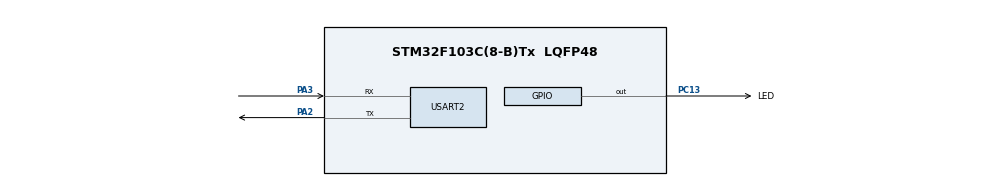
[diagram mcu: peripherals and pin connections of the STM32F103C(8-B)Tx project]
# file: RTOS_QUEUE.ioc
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Mcu.Family=STM32F1
PC15-OSC32_OUT.Mode=LSE-External-Oscillator
FREERTOS.Tasks01=xTaskHandler1,24,128,vTask1_DisplayMenu,Default,NULL,Dynamic,NULL,NULL
PD1-OSC_OUT.Mode=HSE-External-Oscillator
PC13-TAMPER-RTC.Signal=GPIO_Output
PD0-OSC_IN.Signal=RCC_OSC_IN
PC14-OSC32_IN.Signal=RCC_OSC32_IN
ProjectManager.StackSize=0x400
VP_FREERTOS_VS_CMSIS_V2.Mode=CMSIS_V2
PD1-OSC_OUT.Signal=RCC_OSC_OUT
FREERTOS.configUSE_IDLE_HOOK=1
PA13.Signal=SYS_JTMS-SWDIO
PA3.Mode=Asynchronous
VP_SYS_VS_tim3.Mode=TIM3
ProjectManager.TargetToolchain=STM32CubeIDE
FREERTOS.configUSE_MALLOC_FAILED_HOOK=1
PC15-OSC32_OUT.Signal=RCC_OSC32_OUT
PD0-OSC_IN.Mode=HSE-External-Oscillator
board=custom
PC13-TAMPER-RTC.GPIO_Label=LED
NVIC.TIM3_IRQn=true\:0\:0\:false\:false\:true\:false\:false\:true
RCC.APB2Freq_Value=8000000
PC14-OSC32_IN.Mode=LSE-External-Oscillator
PC13-TAMPER-RTC.PinState=GPIO_PIN_RESET
PA14.Mode=Serial_Wire
PA13.Mode=Serial_Wire
Mcu.Name=STM32F103C(8-B)Tx
PA2.Signal=USART2_TX
Mcu.Package=LQFP48
NVIC.TimeBase=TIM3_IRQn
USART2.VirtualMode=VM_ASYNC
NVIC.TimeBaseIP=TIM3
PA14.Signal=SYS_JTCK-SWCLK
ProjectManager.HeapSize=0x200
NVIC.PriorityGroup=NVIC_PRIORITYGROUP_4
PA2.Mode=Asynchronous
RCC.APB1Freq_Value=8000000
PA3.Signal=USART2_RX

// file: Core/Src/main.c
/* USER CODE BEGIN Header */
/**
  ******************************************************************************
  * @file           : main.c
  * @brief          : Main program body
  ******************************************************************************
  * @attention
  *
  * <h2><center>&copy; Copyright (c) 2021 STMicroelectronics.
  * All rights reserved.</center></h2>
  *
  * This software component is licensed by ST under BSD 3-Clause license,
  * the "License"; You may not use this file except in compliance with the
  * License. You may obtain a copy of the License at:
  *                        opensource.org/licenses/BSD-3-Clause
  *
  ******************************************************************************
  */
/* USER CODE END Header */
#include "main.h"
#include "cmsis_os.h"
#include "usart.h"
#include "gpio.h"

void SystemClock_Config(void);
void MX_FREERTOS_Init(void);

int main(void)
{

  /* MCU Configuration--------------------------------------------------------*/

  /* Reset of all peripherals, Initializes the Flash interface and the Systick. */
  HAL_Init();

  /* Configure the system clock */
  SystemClock_Config();

  /* Initialize all configured peripherals */
  MX_GPIO_Init();
  MX_USART2_UART_Init();

  /* Init scheduler */
  osKernelInitialize();  /* Call init function for freertos objects (in freertos.c) */
  MX_FREERTOS_Init();
  /* Start scheduler */
  osKernelStart();

  /* We should never get here as control is now taken by the scheduler */
  /* Infinite loop */
  while (1)
  {

  }
}

void SystemClock_Config(void)
{
  RCC_OscInitTypeDef RCC_OscInitStruct = {0};
  RCC_ClkInitTypeDef RCC_ClkInitStruct = {0};

  /** Initializes the RCC Oscillators according to the specified parameters
  * in the RCC_OscInitTypeDef structure.
  */
  RCC_OscInitStruct.OscillatorType = RCC_OSCILLATORTYPE_HSI;
  RCC_OscInitStruct.HSIState = RCC_HSI_ON;
  RCC_OscInitStruct.HSICalibrationValue = RCC_HSICALIBRATION_DEFAULT;
  RCC_OscInitStruct.PLL.PLLState = RCC_PLL_NONE;
  if (HAL_RCC_OscConfig(&RCC_OscInitStruct) != HAL_OK)
  {
    Error_Handler();
  }
  /** Initializes the CPU, AHB and APB buses clocks
  */
  RCC_ClkInitStruct.ClockType = RCC_CLOCKTYPE_HCLK|RCC_CLOCKTYPE_SYSCLK
                              |RCC_CLOCKTYPE_PCLK1|RCC_CLOCKTYPE_PCLK2;
  RCC_ClkInitStruct.SYSCLKSource = RCC_SYSCLKSOURCE_HSI;
  RCC_ClkInitStruct.AHBCLKDivider = RCC_SYSCLK_DIV1;
  RCC_ClkInitStruct.APB1CLKDivider = RCC_HCLK_DIV1;
  RCC_ClkInitStruct.APB2CLKDivider = RCC_HCLK_DIV1;

  if (HAL_RCC_ClockConfig(&RCC_ClkInitStruct, FLASH_LATENCY_0) != HAL_OK)
  {
    Error_Handler();
  }
}

 /**
  * @brief  Period elapsed callback in non blocking mode
  * @note   This function is called  when TIM3 interrupt took place, inside
  * HAL_TIM_IRQHandler(). It makes a direct call to HAL_IncTick() to increment
  * a global variable "uwTick" used as application time base.
  * @param  htim : TIM handle
  * @retval None
  */
void HAL_TIM_PeriodElapsedCallback(TIM_HandleTypeDef *htim)
{
  if (htim->Instance == TIM3) {
    HAL_IncTick();
  }
}

void Error_Handler(void)
{
  __disable_irq();
  while (1)
  {
  }
}

/************************ (C) COPYRIGHT STMicroelectronics *****END OF FILE****/

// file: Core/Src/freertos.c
/* USER CODE BEGIN Header */
/**
  ******************************************************************************
  * File Name          : freertos.c
  * Description        : Code for freertos applications
  ******************************************************************************
  * @attention
  *
  * <h2><center>&copy; Copyright (c) 2021 STMicroelectronics.
  * All rights reserved.</center></h2>
  *
  * This software component is licensed by ST under Ultimate Liberty license
  * SLA0044, the "License"; You may not use this file except in compliance with
  * the License. You may obtain a copy of the License at:
  *                             www.st.com/SLA0044
  *
  ******************************************************************************
  */
/* USER CODE END Header */

#include "FreeRTOS.h"
#include "task.h"
#include "main.h"
#include "cmsis_os.h"

/* USER CODE BEGIN Variables */

TaskHandle_t xTaskHandler2= NULL;
TaskHandle_t xTaskHandler3= NULL;
TaskHandle_t xTaskHandler4= NULL;
/* USER CODE END Variables */
/* Definitions for xTaskHandler1 */
osThreadId_t xTaskHandler1Handle;
const osThreadAttr_t xTaskHandler1_attributes = {
  .name = "xTaskHandler1",
  .stack_size = 128 * 4,
  .priority = (osPriority_t) osPriorityNormal,
};

/* USER CODE BEGIN FunctionPrototypes */
void vTask2_CmdHandling( void *argument);
void vTask3_CmdProcessing( void *argument);
void vTask4_UartWrite( void *argument);
/* USER CODE END FunctionPrototypes */

void vTask1_DisplayMenu(void *argument);

void MX_FREERTOS_Init(void); /* (MISRA C 2004 rule 8.1) */

/* Hook prototypes */
void vApplicationIdleHook(void);
void vApplicationMallocFailedHook(void);

/* USER CODE BEGIN 2 */
void vApplicationIdleHook( void )
{
	asm volatile ("wfi");
}
/* USER CODE END 2 */

/* USER CODE BEGIN 5 */
void vApplicationMallocFailedHook(void)
{

}
/* USER CODE END 5 */

void MX_FREERTOS_Init(void) {

  /* Create the thread(s) */
  /* creation of xTaskHandler1 */
  xTaskHandler1Handle = osThreadNew(vTask1_DisplayMenu, NULL, &xTaskHandler1_attributes);

  /* USER CODE BEGIN RTOS_THREADS */
  /* add threads, ... */
  xTaskCreate(vTask2_CmdHandling,   "Task-2", 128u, NULL, 24u, &xTaskHandler2);
  xTaskCreate(vTask3_CmdProcessing, "Task-3", 128u, NULL, 24u, &xTaskHandler3);
  xTaskCreate(vTask4_UartWrite,     "Task-4", 128u, NULL, 24u, &xTaskHandler4);
  /* USER CODE END RTOS_THREADS */

}

void vTask1_DisplayMenu(void *argument)
{
  /* USER CODE BEGIN vTask1_DisplayMenu */
  /* Infinite loop */
  for(;;)
  {
    osDelay(pdMS_TO_TICKS(1000u));
  }
  /* USER CODE END vTask1_DisplayMenu */
}

/* USER CODE BEGIN Application */

void vTask2_CmdHandling( void *argument){
	while(1){
		osDelay(pdMS_TO_TICKS(1000u));
	}
}

void vTask3_CmdProcessing( void *argument){
	while(1){
		osDelay(pdMS_TO_TICKS(1000u));
	}
}

void vTask4_UartWrite( void *argument){
	while(1){
		osDelay(pdMS_TO_TICKS(1000u));
	}
}
/* USER CODE END Application */

/************************ (C) COPYRIGHT STMicroelectronics *****END OF FILE****/
